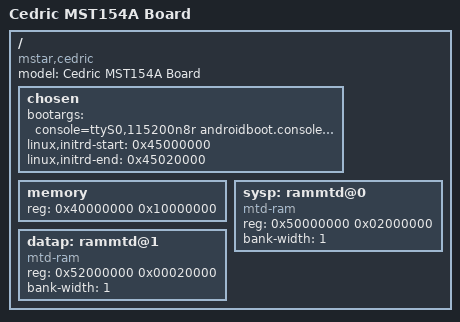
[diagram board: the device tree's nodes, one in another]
/*
 * Copyright (c) 2014 MundoReader S.L.
 * Author: Matthias Brugger <matthias.bgg@gmail.com>
 *
 * This program is free software; you can redistribute it and/or modify
 * it under the terms of the GNU General Public License as published by
 * the Free Software Foundation; either version 2 of the License, or
 * (at your option) any later version.
 *
 * This program is distributed in the hope that it will be useful,
 * but WITHOUT ANY WARRANTY; without even the implied warranty of
 * MERCHANTABILITY or FITNESS FOR A PARTICULAR PURPOSE.  See the
 * GNU General Public License for more details.
 */

/dts-v1/;
#include "cedric.dtsi"

/ {
	model = "Cedric MST154A Board";
	compatible = "mstar,cedric";
	

	chosen {
	    bootargs = "console=ttyS0,115200n8r androidboot.console=ttyS0 root=/dev/ram rootwait";
		/*bootargs = "console=ttyS0,115200n8r androidboot.console=ttyS0 root=/dev/ram rootwait sysp=squashfs:/dev/block/mtdblock0 datap=jffs2:/dev/block/mtdblock1";*/
		
		linux,initrd-start = <0x45000000>;
		linux,initrd-end =   <0x45020000>;
	};
	
	

	memory {
		reg = <0x40000000 0x10000000>;
	};
	
	sysp:rammtd@0 {
        compatible = "mtd-ram";
        reg= <0x50000000 0x02000000>;
        bank-width = <1>;
    };
    
    datap:rammtd@1 {
        compatible = "mtd-ram";
        reg= <0x52000000 0x00020000>;
        bank-width = <1>;
    };
        
};
